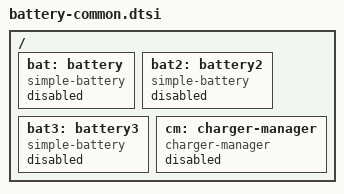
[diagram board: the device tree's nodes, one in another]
// SPDX-License-Identifier: (Licenseref-Unisoc-General-1.0 OR GPL-2.0-only)
/*
 * battery-common.dtsi - Unisoc platform device
 *
 * Copyright 2022 Unisoc(Shanghai) Technologies Co.Ltd
 *
 * Licensed under the Unisoc General Software License, version 1.0 (the
 * License);
 * you may not use this file except in compliance with the License.
 * You may obtain a copy of the License at
 * https://www.unisoc.com/en_us/license/UNISOC_GENERAL_LICENSE_V1.0-EN_US
 * Software distributed under the License is distributed on an "AS IS" BASIS,
 * WITHOUT WARRANTIES OF ANY KIND, either express or implied.
 * See the Unisoc General Software License, version 1.0 for more details.
 *
 * Alternatively you can use and distribute this file under the terms of the
 * GNU General Public License version 2, provided that it has to be used
 *  (including but not limited to combining, linking) with any other file under
 * the GNU General Public License version 2 on platforms that use Unisoc Chips.
 */

/ {
	bat: battery {
		compatible = "simple-battery";
		status = "disabled";
	};

	bat2: battery2 {
		compatible = "simple-battery";
		status = "disabled";
	};

	bat3: battery3 {
		compatible = "simple-battery";
		status = "disabled";
	};

	cm: charger-manager {
		compatible = "charger-manager";
		status = "disabled";
	};
};
